AUTOSAR XML (schema 00048)
package /SoftwareTypes/ComponentTypes
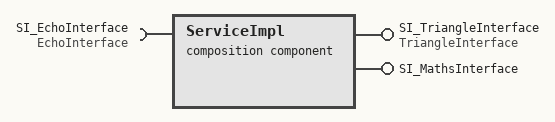
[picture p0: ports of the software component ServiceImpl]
  composition sw component type ServiceImpl
    require port SI_EchoInterface: nonqueued-receiver-com-spec{data-element=Echo, max-delta-counter-init=-1, filter=data-filter-type=ALWAYS}, required-interface=EchoInterface
    provide port SI_TriangleInterface: nonqueued-sender-com-spec=Triangle, provided-interface=TriangleInterface
    provide port SI_MathsInterface: provided-interface=SI_MathsInterface
      provided-com-specs:
        operation=Add, queue-length=1
        operation=Divide, queue-length=1
        operation=Multiply, queue-length=1
        operation=Substract, queue-length=1
    component C_Basics_MyECU: type=C_Basics
    component P_Maths_MyECU: type=P_Maths
    delegate P_Maths_MyECU.TriangleInterface <-> outer port SI_TriangleInterface
    delegate C_Basics_MyECU.EchoInterface <-> outer port SI_EchoInterface
    delegate P_Maths_MyECU.SI_MathsInterface <-> outer port SI_MathsInterface
